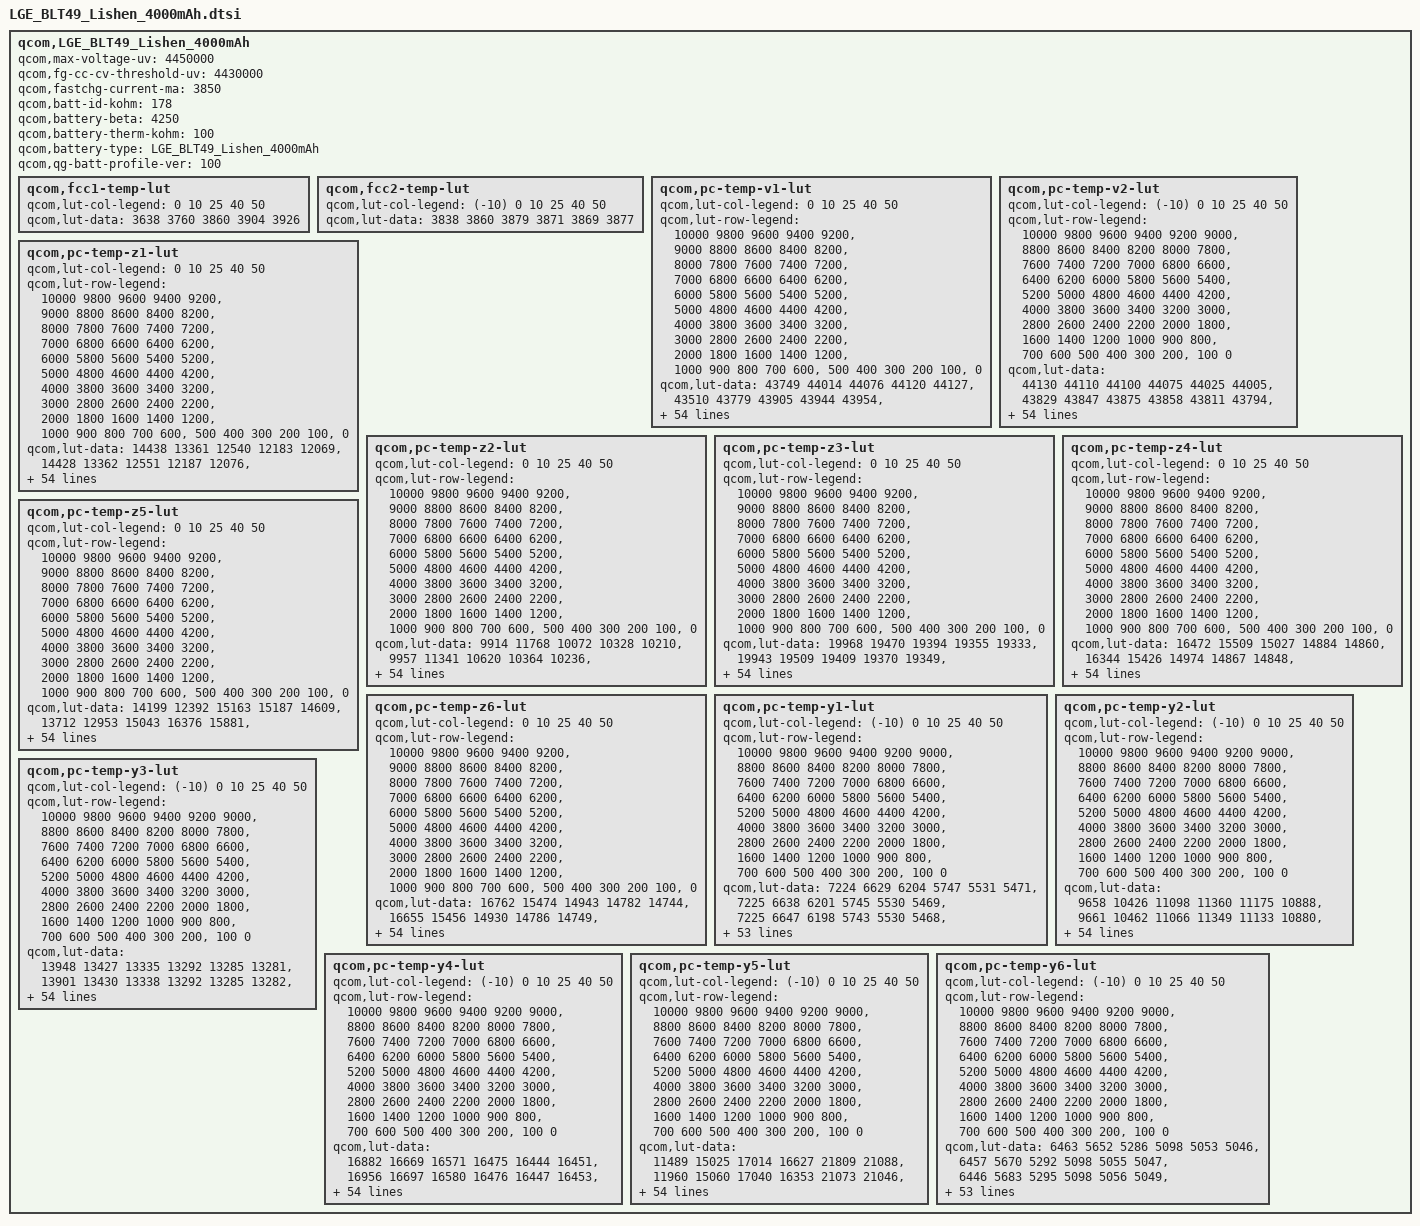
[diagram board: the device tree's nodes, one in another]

qcom,LGE_BLT49_Lishen_4000mAh {
    /* 4570460_LGE_BLT49lish_4000mAh_averaged_MasterSlave_May18th2020 */
    qcom,max-voltage-uv = <4450000>;
    qcom,fg-cc-cv-threshold-uv = <4430000>;
    qcom,fastchg-current-ma = <3850>;
    qcom,batt-id-kohm = <178>;
    qcom,battery-beta = <4250>;
    qcom,battery-therm-kohm = <100>;
    qcom,battery-type = "LGE_BLT49_Lishen_4000mAh";
    qcom,qg-batt-profile-ver = <100>;

	qcom,fcc1-temp-lut {
		qcom,lut-col-legend = <0 10 25 40 50>;
		qcom,lut-data = <3638 3760 3860 3904 3926>;
	};

	qcom,fcc2-temp-lut {
		qcom,lut-col-legend = <(-10) 0 10 25 40 50>;
		qcom,lut-data = <3838 3860 3879 3871 3869 3877>;
	};

	qcom,pc-temp-v1-lut {
		qcom,lut-col-legend = <0 10 25 40 50>;
		qcom,lut-row-legend = <10000 9800 9600 9400 9200>,
			<9000 8800 8600 8400 8200>,
			<8000 7800 7600 7400 7200>,
			<7000 6800 6600 6400 6200>,
			<6000 5800 5600 5400 5200>,
			<5000 4800 4600 4400 4200>,
			<4000 3800 3600 3400 3200>,
			<3000 2800 2600 2400 2200>,
			<2000 1800 1600 1400 1200>,
			<1000 900 800 700 600>,
			<500 400 300 200 100>,
			<0>;
		qcom,lut-data = <43749 44014 44076 44120 44127>,
			<43510 43779 43905 43944 43954>,
			<43273 43545 43719 43758 43769>,
			<43036 43312 43521 43561 43573>,
			<42802 43079 43309 43355 43368>,
			<42569 42846 43081 43136 43151>,
			<42337 42615 42847 42908 42922>,
			<42106 42384 42609 42678 42691>,
			<41876 42152 42368 42444 42455>,
			<41652 41916 42130 42208 42218>,
			<41432 41686 41896 41971 41983>,
			<41216 41462 41666 41735 41749>,
			<41005 41244 41442 41506 41520>,
			<40799 41034 41222 41284 41297>,
			<40598 40830 41008 41067 41078>,
			<40403 40632 40801 40856 40865>,
			<40213 40436 40600 40651 40657>,
			<40034 40242 40409 40454 40457>,
			<39866 40056 40227 40271 40271>,
			<39708 39883 40032 40082 40086>,
			<39559 39719 39794 39850 39870>,
			<39417 39546 39542 39582 39616>,
			<39285 39355 39332 39359 39389>,
			<39160 39163 39148 39194 39216>,
			<39042 38985 38993 39054 39068>,
			<38931 38816 38870 38922 38931>,
			<38829 38678 38765 38800 38803>,
			<38733 38581 38664 38689 38686>,
			<38646 38503 38567 38587 38580>,
			<38567 38432 38476 38492 38482>,
			<38495 38365 38392 38404 38393>,
			<38433 38306 38314 38321 38311>,
			<38381 38255 38244 38244 38236>,
			<38333 38211 38183 38176 38166>,
			<38287 38170 38128 38112 38099>,
			<38243 38133 38074 38047 38028>,
			<38197 38096 38026 37982 37950>,
			<38140 38048 37970 37910 37866>,
			<38074 37976 37892 37824 37773>,
			<37995 37887 37796 37724 37669>,
			<37892 37784 37694 37618 37559>,
			<37767 37662 37583 37506 37443>,
			<37621 37522 37453 37378 37312>,
			<37461 37366 37291 37220 37146>,
			<37311 37228 37157 37091 37028>,
			<37204 37140 37070 37009 36953>,
			<37166 37112 37043 36985 36930>,
			<37131 37081 37027 36966 36909>,
			<37094 37051 37005 36948 36887>,
			<37015 36986 36947 36885 36815>,
			<36787 36762 36704 36617 36526>,
			<36344 36314 36264 36182 36088>,
			<35767 35740 35699 35620 35523>,
			<34988 34962 34933 34863 34758>,
			<33714 33717 33726 33678 33555>,
			<30000 30000 30000 30000 30000>;
	};

	qcom,pc-temp-v2-lut {
		qcom,lut-col-legend = <(-10) 0 10 25 40 50>;
		qcom,lut-row-legend = <10000 9800 9600 9400 9200 9000>,
			<8800 8600 8400 8200 8000 7800>,
			<7600 7400 7200 7000 6800 6600>,
			<6400 6200 6000 5800 5600 5400>,
			<5200 5000 4800 4600 4400 4200>,
			<4000 3800 3600 3400 3200 3000>,
			<2800 2600 2400 2200 2000 1800>,
			<1600 1400 1200 1000 900 800>,
			<700 600 500 400 300 200>,
			<100 0>;
		qcom,lut-data = <44130 44110 44100 44075 44025 44005>,
			<43829 43847 43875 43858 43811 43794>,
			<43541 43594 43649 43640 43595 43581>,
			<43266 43353 43427 43421 43378 43367>,
			<43008 43126 43207 43202 43161 43152>,
			<42756 42900 42983 42979 42940 42933>,
			<42503 42662 42749 42746 42710 42703>,
			<42253 42419 42509 42508 42474 42468>,
			<42005 42178 42269 42271 42239 42233>,
			<41760 41940 42029 42035 42003 41997>,
			<41518 41706 41793 41801 41769 41763>,
			<41276 41472 41562 41570 41539 41533>,
			<41036 41242 41337 41342 41313 41307>,
			<40796 41011 41111 41119 41092 41087>,
			<40553 40781 40886 40904 40877 40872>,
			<40311 40550 40659 40694 40669 40664>,
			<40072 40316 40422 40490 40468 40464>,
			<39834 40075 40172 40295 40277 40272>,
			<39608 39842 39932 40091 40080 40076>,
			<39402 39623 39706 39856 39862 39865>,
			<39210 39416 39493 39608 39633 39648>,
			<39028 39223 39300 39383 39415 39433>,
			<38855 39044 39125 39175 39197 39209>,
			<38692 38877 38964 38991 39002 39009>,
			<38542 38725 38818 38840 38849 38854>,
			<38399 38585 38685 38712 38721 38725>,
			<38279 38448 38561 38593 38603 38606>,
			<38185 38301 38445 38483 38493 38494>,
			<38107 38165 38337 38381 38392 38391>,
			<38036 38067 38237 38286 38298 38296>,
			<37975 37995 38146 38198 38212 38209>,
			<37916 37932 38056 38116 38130 38126>,
			<37854 37878 37961 38041 38052 38049>,
			<37790 37829 37870 37969 37976 37972>,
			<37727 37778 37801 37893 37892 37880>,
			<37663 37725 37748 37813 37798 37771>,
			<37598 37668 37695 37731 37701 37659>,
			<37531 37604 37638 37645 37602 37554>,
			<37462 37533 37576 37556 37501 37453>,
			<37391 37452 37503 37466 37404 37355>,
			<37316 37357 37414 37377 37314 37264>,
			<37237 37253 37312 37281 37222 37169>,
			<37153 37150 37194 37164 37106 37049>,
			<37064 37045 37063 37034 36976 36921>,
			<36964 36943 36951 36934 36886 36835>,
			<36843 36845 36864 36868 36829 36781>,
			<36770 36795 36835 36853 36816 36768>,
			<36686 36741 36805 36838 36802 36753>,
			<36577 36676 36764 36809 36773 36719>,
			<36411 36575 36676 36734 36676 36598>,
			<36174 36369 36424 36469 36366 36256>,
			<35815 35973 35920 35992 35881 35762>,
			<35292 35381 35267 35364 35252 35119>,
			<34486 34507 34357 34497 34372 34228>,
			<33122 33078 32993 33192 33113 32956>,
			<28180 27841 27854 28000 28702 28124>;
	};

	qcom,pc-temp-z1-lut {
		qcom,lut-col-legend = <0 10 25 40 50>;
		qcom,lut-row-legend = <10000 9800 9600 9400 9200>,
			<9000 8800 8600 8400 8200>,
			<8000 7800 7600 7400 7200>,
			<7000 6800 6600 6400 6200>,
			<6000 5800 5600 5400 5200>,
			<5000 4800 4600 4400 4200>,
			<4000 3800 3600 3400 3200>,
			<3000 2800 2600 2400 2200>,
			<2000 1800 1600 1400 1200>,
			<1000 900 800 700 600>,
			<500 400 300 200 100>,
			<0>;
		qcom,lut-data = <14438 13361 12540 12183 12069>,
			<14428 13362 12551 12187 12076>,
			<14417 13364 12561 12190 12083>,
			<14404 13366 12564 12192 12089>,
			<14391 13366 12558 12192 12091>,
			<14377 13363 12554 12192 12091>,
			<14364 13360 12549 12191 12090>,
			<14350 13356 12544 12191 12091>,
			<14335 13352 12540 12190 12094>,
			<14321 13348 12537 12190 12097>,
			<14307 13344 12534 12191 12100>,
			<14294 13333 12533 12192 12102>,
			<14284 13318 12533 12193 12103>,
			<14274 13312 12534 12193 12104>,
			<14263 13318 12535 12194 12105>,
			<14246 13326 12535 12195 12106>,
			<14217 13330 12535 12195 12108>,
			<14190 13334 12536 12196 12110>,
			<14172 13337 12540 12199 12111>,
			<14158 13341 12544 12202 12113>,
			<14150 13344 12547 12204 12115>,
			<14146 13345 12551 12206 12116>,
			<14143 13350 12555 12209 12118>,
			<14138 13357 12559 12212 12122>,
			<14121 13359 12563 12215 12126>,
			<14107 13362 12567 12219 12129>,
			<14111 13366 12572 12223 12131>,
			<14126 13371 12577 12227 12134>,
			<14138 13378 12581 12231 12138>,
			<14138 13385 12586 12235 12143>,
			<14134 13394 12590 12238 12147>,
			<14134 13403 12596 12241 12150>,
			<14141 13409 12601 12244 12153>,
			<14152 13414 12606 12248 12157>,
			<14161 13421 12612 12253 12160>,
			<14170 13435 12620 12258 12163>,
			<14181 13453 12628 12263 12166>,
			<14199 13465 12636 12268 12169>,
			<14227 13477 12645 12272 12173>,
			<14250 13486 12653 12277 12178>,
			<14266 13490 12660 12281 12182>,
			<14277 13495 12665 12287 12185>,
			<14281 13507 12672 12291 12189>,
			<14287 13527 12682 12294 12192>,
			<14268 13522 12691 12300 12196>,
			<14242 13528 12691 12302 12198>,
			<14262 13523 12694 12303 12199>,
			<14261 13517 12698 12306 12199>,
			<14258 13512 12700 12308 12201>,
			<14255 13531 12712 12313 12207>,
			<14278 13561 12726 12323 12213>,
			<14302 13584 12737 12333 12222>,
			<14294 13592 12766 12348 12236>,
			<14347 13615 12789 12371 12258>,
			<14347 13615 12789 12371 12258>,
			<14347 13615 12789 12371 12258>;
	};

	qcom,pc-temp-z2-lut {
		qcom,lut-col-legend = <0 10 25 40 50>;
		qcom,lut-row-legend = <10000 9800 9600 9400 9200>,
			<9000 8800 8600 8400 8200>,
			<8000 7800 7600 7400 7200>,
			<7000 6800 6600 6400 6200>,
			<6000 5800 5600 5400 5200>,
			<5000 4800 4600 4400 4200>,
			<4000 3800 3600 3400 3200>,
			<3000 2800 2600 2400 2200>,
			<2000 1800 1600 1400 1200>,
			<1000 900 800 700 600>,
			<500 400 300 200 100>,
			<0>;
		qcom,lut-data = <9914 11768 10072 10328 10210>,
			<9957 11341 10620 10364 10236>,
			<9993 10918 11041 10388 10256>,
			<10022 10549 11269 10402 10269>,
			<10042 10290 11251 10405 10275>,
			<10055 10199 11080 10393 10272>,
			<10060 10310 10916 10372 10266>,
			<10054 10451 10781 10423 10260>,
			<10040 10445 10639 10657 10242>,
			<10030 10284 10558 10786 10218>,
			<10023 10161 10544 10606 10196>,
			<10019 10157 10580 10349 10170>,
			<10016 10166 10677 10354 10160>,
			<10015 10186 10822 10653 10159>,
			<10014 10325 10895 10901 10160>,
			<10013 10485 10928 10950 10167>,
			<10012 10486 10958 10974 10182>,
			<10011 10367 10998 11002 10194>,
			<10011 10280 11046 11041 10197>,
			<10011 10286 11066 11066 10200>,
			<10011 10309 10881 10926 10208>,
			<10019 10329 10593 10575 10236>,
			<10033 10348 10491 10404 10261>,
			<10047 10364 10454 10353 10271>,
			<10066 10372 10439 10319 10279>,
			<10083 10378 10451 10332 10281>,
			<10091 10382 10479 10401 10299>,
			<10096 10385 10494 10442 10314>,
			<10102 10388 10499 10399 10286>,
			<10114 10392 10500 10333 10224>,
			<10128 10399 10500 10314 10181>,
			<10124 10407 10500 10310 10149>,
			<9933 10416 10503 10311 10131>,
			<9689 10426 10514 10320 10141>,
			<9614 10436 10529 10338 10173>,
			<9591 10446 10541 10358 10208>,
			<9580 10456 10551 10385 10251>,
			<9575 10467 10562 10416 10295>,
			<9571 10480 10580 10459 10332>,
			<9570 10495 10601 10510 10365>,
			<9582 10509 10613 10527 10376>,
			<9604 10523 10620 10518 10374>,
			<9620 10542 10627 10502 10369>,
			<9621 10575 10633 10477 10360>,
			<9473 10843 10720 10474 10362>,
			<9478 10961 10744 10505 10347>,
			<9542 11008 10754 10501 10377>,
			<9575 11012 10788 10536 10364>,
			<9585 11045 10862 10947 10419>,
			<9582 11053 10853 10960 10497>,
			<9558 10971 10857 10530 10344>,
			<9480 10847 10812 10381 10183>,
			<9380 10591 10828 10357 10126>,
			<9294 10421 10715 10888 10053>,
			<9294 10421 10715 10888 10053>,
			<9294 10421 10715 10888 10053>;
	};

	qcom,pc-temp-z3-lut {
		qcom,lut-col-legend = <0 10 25 40 50>;
		qcom,lut-row-legend = <10000 9800 9600 9400 9200>,
			<9000 8800 8600 8400 8200>,
			<8000 7800 7600 7400 7200>,
			<7000 6800 6600 6400 6200>,
			<6000 5800 5600 5400 5200>,
			<5000 4800 4600 4400 4200>,
			<4000 3800 3600 3400 3200>,
			<3000 2800 2600 2400 2200>,
			<2000 1800 1600 1400 1200>,
			<1000 900 800 700 600>,
			<500 400 300 200 100>,
			<0>;
		qcom,lut-data = <19968 19470 19394 19355 19333>,
			<19943 19509 19409 19370 19349>,
			<19908 19550 19424 19385 19364>,
			<19869 19589 19439 19397 19377>,
			<19832 19623 19454 19405 19387>,
			<19803 19648 19471 19408 19395>,
			<19790 19670 19482 19410 19401>,
			<19788 19686 19484 19415 19404>,
			<19791 19682 19482 19423 19405>,
			<19793 19650 19479 19427 19406>,
			<19796 19619 19473 19418 19404>,
			<19798 19606 19471 19405 19398>,
			<19798 19597 19476 19403 19393>,
			<19796 19595 19484 19408 19388>,
			<19793 19611 19484 19412 19383>,
			<19788 19629 19481 19410 19380>,
			<19777 19625 19476 19406 19378>,
			<19764 19590 19472 19403 19376>,
			<19750 19563 19468 19399 19372>,
			<19735 19559 19465 19395 19368>,
			<19719 19557 19464 19393 19367>,
			<19702 19557 19464 19392 19367>,
			<19683 19573 19462 19389 19367>,
			<19665 19593 19453 19379 19369>,
			<19646 19598 19443 19370 19373>,
			<19628 19599 19435 19375 19380>,
			<19611 19598 19429 19398 19400>,
			<19596 19594 19428 19413 19414>,
			<19580 19588 19429 19411 19411>,
			<19564 19582 19431 19407 19405>,
			<19545 19579 19433 19404 19399>,
			<19522 19575 19438 19400 19391>,
			<19484 19571 19441 19396 19384>,
			<19444 19568 19440 19391 19375>,
			<19421 19564 19439 19386 19366>,
			<19404 19561 19438 19381 19362>,
			<19395 19558 19436 19377 19360>,
			<19393 19554 19433 19374 19359>,
			<19391 19551 19432 19374 19358>,
			<19391 19547 19430 19375 19357>,
			<19391 19542 19427 19375 19356>,
			<19390 19534 19422 19372 19357>,
			<19384 19525 19418 19370 19360>,
			<19360 19511 19416 19369 19366>,
			<19277 19447 19403 19365 19360>,
			<19276 19366 19394 19358 19351>,
			<19271 19308 19394 19350 19342>,
			<19269 19300 19371 19345 19339>,
			<19269 19293 19356 19304 19333>,
			<19269 19291 19369 19304 19326>,
			<19269 19296 19361 19348 19349>,
			<19272 19301 19362 19360 19359>,
			<19278 19306 19349 19359 19363>,
			<19290 19312 19345 19309 19364>,
			<19290 19312 19345 19309 19364>,
			<19290 19312 19345 19309 19364>;
	};

	qcom,pc-temp-z4-lut {
		qcom,lut-col-legend = <0 10 25 40 50>;
		qcom,lut-row-legend = <10000 9800 9600 9400 9200>,
			<9000 8800 8600 8400 8200>,
			<8000 7800 7600 7400 7200>,
			<7000 6800 6600 6400 6200>,
			<6000 5800 5600 5400 5200>,
			<5000 4800 4600 4400 4200>,
			<4000 3800 3600 3400 3200>,
			<3000 2800 2600 2400 2200>,
			<2000 1800 1600 1400 1200>,
			<1000 900 800 700 600>,
			<500 400 300 200 100>,
			<0>;
		qcom,lut-data = <16472 15509 15027 14884 14860>,
			<16344 15426 14974 14867 14848>,
			<16220 15342 14925 14849 14835>,
			<16099 15259 14880 14831 14821>,
			<15981 15176 14839 14813 14806>,
			<15866 15091 14800 14795 14790>,
			<15755 14987 14770 14775 14773>,
			<15644 14901 14750 14751 14756>,
			<15537 14883 14735 14719 14738>,
			<15446 14882 14730 14700 14723>,
			<15367 14880 14713 14700 14714>,
			<15299 14870 14695 14702 14708>,
			<15240 14848 14678 14697 14703>,
			<15189 14817 14655 14677 14698>,
			<15147 14760 14645 14662 14695>,
			<15115 14707 14640 14658 14691>,
			<15089 14706 14638 14654 14687>,
			<15069 14739 14636 14653 14685>,
			<15056 14763 14636 14653 14683>,
			<15045 14759 14636 14653 14683>,
			<15038 14751 14671 14677 14695>,
			<15034 14747 14734 14750 14752>,
			<15030 14751 14770 14792 14790>,
			<15029 14758 14796 14801 14787>,
			<15030 14770 14809 14806 14779>,
			<15033 14798 14803 14797 14766>,
			<15039 14815 14787 14757 14733>,
			<15051 14811 14771 14725 14707>,
			<15065 14801 14756 14712 14700>,
			<15078 14791 14741 14703 14695>,
			<15091 14783 14727 14695 14691>,
			<15111 14775 14714 14688 14686>,
			<15150 14767 14705 14683 14682>,
			<15187 14760 14699 14679 14679>,
			<15195 14753 14695 14676 14675>,
			<15194 14744 14693 14676 14675>,
			<15192 14736 14692 14678 14677>,
			<15180 14730 14692 14682 14681>,
			<15147 14727 14695 14688 14688>,
			<15113 14724 14701 14696 14699>,
			<15086 14720 14702 14699 14703>,
			<15061 14715 14693 14692 14694>,
			<15042 14710 14686 14689 14688>,
			<15022 14702 14684 14691 14692>,
			<14992 14697 14665 14676 14677>,
			<14986 14773 14656 14665 14666>,
			<14981 14830 14650 14663 14663>,
			<14975 14832 14660 14653 14650>,
			<14969 14833 14669 14682 14637>,
			<14964 14833 14650 14677 14638>,
			<14971 14834 14674 14662 14659>,
			<15000 14851 14683 14661 14661>,
			<15025 14858 14703 14667 14662>,
			<15048 14867 14713 14725 14664>,
			<15048 14867 14713 14725 14664>,
			<15048 14867 14713 14725 14664>;
	};

	qcom,pc-temp-z5-lut {
		qcom,lut-col-legend = <0 10 25 40 50>;
		qcom,lut-row-legend = <10000 9800 9600 9400 9200>,
			<9000 8800 8600 8400 8200>,
			<8000 7800 7600 7400 7200>,
			<7000 6800 6600 6400 6200>,
			<6000 5800 5600 5400 5200>,
			<5000 4800 4600 4400 4200>,
			<4000 3800 3600 3400 3200>,
			<3000 2800 2600 2400 2200>,
			<2000 1800 1600 1400 1200>,
			<1000 900 800 700 600>,
			<500 400 300 200 100>,
			<0>;
		qcom,lut-data = <14199 12392 15163 15187 14609>,
			<13712 12953 15043 16376 15881>,
			<13460 13618 15180 17495 17109>,
			<13397 14354 15484 18449 18287>,
			<13480 15124 16064 19136 19412>,
			<13663 15915 17345 19528 20472>,
			<13905 16987 18618 19873 21490>,
			<14269 17897 19830 20865 22519>,
			<14757 17987 20873 23178 23632>,
			<15234 17567 21234 24521 24614>,
			<15695 17222 22894 23938 25328>,
			<16163 17312 25167 23100 25920>,
			<16646 17682 28340 23989 26118>,
			<17200 18471 32903 28587 25977>,
			<17653 22874 35618 32401 25814>,
			<17890 27868 37387 33686 26204>,
			<18060 27917 38681 34980 27711>,
			<18133 24164 39244 35473 28684>,
			<18063 21384 39510 35493 28852>,
			<17886 21625 39960 35439 28865>,
			<17670 22640 42436 34180 28212>,
			<17350 24486 45637 30549 25344>,
			<16950 33307 44892 26894 22348>,
			<16558 43640 35775 21956 19930>,
			<16146 46375 27033 17611 17956>,
			<15739 46208 23676 17629 18185>,
			<15371 45007 21411 20172 22217>,
			<15012 41937 20875 22317 26013>,
			<14673 37556 21080 23174 27435>,
			<14369 35203 21478 23849 28374>,
			<14067 34132 22539 24880 28560>,
			<13691 33494 25046 26489 28321>,
			<13100 33308 27544 27764 27950>,
			<12515 33207 29826 28397 27448>,
			<12218 33163 31830 28840 26759>,
			<12032 33327 32990 28941 26528>,
			<11926 33768 33834 28907 27215>,
			<11900 34398 34347 28842 27901>,
			<11884 35851 34474 28696 27243>,
			<11878 37167 34311 28350 25336>,
			<11966 36730 33617 27786 24274>,
			<12086 34490 30914 26197 24272>,
			<12089 32625 29827 25183 24863>,
			<12059 30811 29977 24948 28071>,
			<11698 24642 30727 25637 27293>,
			<11662 17115 29059 24019 22997>,
			<11593 12526 29878 21432 20188>,
			<11557 12341 21172 22286 21129>,
			<11556 12187 18200 18322 22773>,
			<11570 12182 22048 18762 20882>,
			<11626 12297 18723 20079 22006>,
			<11619 12184 17330 20058 20729>,
			<11469 12122 15181 18816 19424>,
			<11407 12069 14528 13993 17863>,
			<11407 12069 14528 13993 17863>,
			<11407 12069 14528 13993 17863>;
	};

	qcom,pc-temp-z6-lut {
		qcom,lut-col-legend = <0 10 25 40 50>;
		qcom,lut-row-legend = <10000 9800 9600 9400 9200>,
			<9000 8800 8600 8400 8200>,
			<8000 7800 7600 7400 7200>,
			<7000 6800 6600 6400 6200>,
			<6000 5800 5600 5400 5200>,
			<5000 4800 4600 4400 4200>,
			<4000 3800 3600 3400 3200>,
			<3000 2800 2600 2400 2200>,
			<2000 1800 1600 1400 1200>,
			<1000 900 800 700 600>,
			<500 400 300 200 100>,
			<0>;
		qcom,lut-data = <16762 15474 14943 14782 14744>,
			<16655 15456 14930 14786 14749>,
			<16552 15433 14917 14787 14753>,
			<16454 15407 14906 14786 14755>,
			<16362 15379 14895 14783 14755>,
			<16279 15350 14886 14778 14753>,
			<16204 15316 14876 14770 14749>,
			<16137 15281 14868 14763 14744>,
			<16077 15253 14859 14756 14739>,
			<16026 15231 14851 14749 14733>,
			<15984 15211 14841 14743 14727>,
			<15947 15192 14832 14738 14722>,
			<15911 15175 14826 14733 14717>,
			<15876 15159 14821 14728 14712>,
			<15844 15143 14816 14725 14708>,
			<15815 15129 14813 14721 14705>,
			<15787 15123 14810 14718 14703>,
			<15763 15120 14807 14716 14700>,
			<15742 15118 14805 14713 14698>,
			<15724 15115 14804 14712 14696>,
			<15707 15113 14820 14722 14700>,
			<15690 15112 14848 14753 14725>,
			<15675 15122 14860 14768 14742>,
			<15661 15137 14866 14768 14743>,
			<15648 15150 14869 14767 14743>,
			<15640 15164 14865 14765 14742>,
			<15640 15172 14856 14761 14739>,
			<15642 15170 14849 14757 14736>,
			<15643 15165 14843 14751 14732>,
			<15643 15161 14839 14746 14727>,
			<15642 15157 14836 14741 14723>,
			<15642 15154 14833 14736 14717>,
			<15638 15151 14831 14732 14711>,
			<15633 15149 14829 14728 14705>,
			<15632 15148 14828 14724 14699>,
			<15632 15147 14828 14723 14697>,
			<15633 15147 14828 14722 14698>,
			<15635 15147 14828 14722 14699>,
			<15642 15147 14830 14724 14701>,
			<15646 15148 14833 14729 14705>,
			<15646 15148 14834 14731 14707>,
			<15644 15148 14829 14727 14705>,
			<15639 15147 14826 14726 14703>,
			<15625 15143 14825 14727 14709>,
			<15583 15117 14814 14719 14700>,
			<15583 15110 14807 14711 14691>,
			<15582 15107 14804 14706 14685>,
			<15584 15106 14799 14699 14677>,
			<15586 15106 14795 14692 14669>,
			<15591 15113 14796 14690 14666>,
			<15607 15127 14806 14708 14689>,
			<15631 15144 14815 14717 14698>,
			<15659 15165 14822 14722 14704>,
			<15692 15194 14834 14727 14710>,
			<15692 15194 14834 14727 14710>,
			<15692 15194 14834 14727 14710>;
	};

	qcom,pc-temp-y1-lut {
		qcom,lut-col-legend = <(-10) 0 10 25 40 50>;
		qcom,lut-row-legend = <10000 9800 9600 9400 9200 9000>,
			<8800 8600 8400 8200 8000 7800>,
			<7600 7400 7200 7000 6800 6600>,
			<6400 6200 6000 5800 5600 5400>,
			<5200 5000 4800 4600 4400 4200>,
			<4000 3800 3600 3400 3200 3000>,
			<2800 2600 2400 2200 2000 1800>,
			<1600 1400 1200 1000 900 800>,
			<700 600 500 400 300 200>,
			<100 0>;
		qcom,lut-data = <7224 6629 6204 5747 5531 5471>,
			<7225 6638 6201 5745 5530 5469>,
			<7225 6647 6198 5743 5530 5468>,
			<7225 6654 6197 5741 5529 5467>,
			<7226 6660 6196 5739 5529 5466>,
			<7226 6662 6196 5738 5529 5466>,
			<7226 6661 6196 5737 5529 5466>,
			<7226 6658 6196 5736 5529 5467>,
			<7227 6656 6194 5735 5529 5467>,
			<7231 6656 6189 5735 5529 5467>,
			<7236 6656 6185 5735 5528 5468>,
			<7243 6657 6186 5735 5528 5468>,
			<7262 6660 6189 5734 5528 5469>,
			<7273 6664 6192 5734 5528 5470>,
			<7264 6671 6191 5735 5528 5470>,
			<7251 6678 6191 5736 5529 5470>,
			<7252 6682 6193 5737 5530 5471>,
			<7276 6687 6199 5737 5531 5473>,
			<7297 6691 6204 5737 5532 5474>,
			<7286 6689 6208 5738 5532 5475>,
			<7262 6685 6212 5740 5533 5476>,
			<7253 6684 6212 5741 5534 5477>,
			<7245 6692 6208 5743 5535 5478>,
			<7234 6702 6205 5744 5536 5479>,
			<7232 6704 6211 5746 5538 5481>,
			<7234 6702 6226 5749 5540 5483>,
			<7236 6699 6231 5751 5542 5484>,
			<7237 6697 6227 5753 5544 5486>,
			<7239 6694 6223 5755 5546 5487>,
			<7239 6695 6225 5758 5548 5488>,
			<7238 6701 6231 5761 5550 5490>,
			<7237 6705 6234 5764 5553 5492>,
			<7238 6701 6232 5767 5555 5494>,
			<7242 6696 6228 5769 5557 5496>,
			<7245 6695 6227 5771 5559 5498>,
			<7245 6696 6227 5774 5561 5499>,
			<7245 6699 6228 5777 5563 5500>,
			<7246 6709 6229 5780 5564 5502>,
			<7249 6728 6231 5783 5565 5504>,
			<7253 6734 6233 5786 5566 5505>,
			<7255 6722 6239 5788 5569 5507>,
			<7257 6710 6247 5791 5571 5508>,
			<7259 6710 6256 5794 5574 5510>,
			<7265 6714 6264 5798 5577 5512>,
			<7274 6719 6262 5804 5580 5515>,
			<7301 6727 6260 5810 5583 5518>,
			<7317 6731 6273 5813 5583 5517>,
			<7335 6737 6280 5816 5583 5518>,
			<7329 6752 6274 5815 5585 5520>,
			<7331 6764 6296 5817 5585 5520>,
			<7397 6781 6298 5822 5588 5524>,
			<7501 6812 6302 5829 5595 5531>,
			<7577 6863 6329 5848 5609 5542>,
			<7708 6990 6388 5874 5625 5559>,
			<7708 6990 6388 5874 5625 5559>,
			<7708 6990 6388 5874 5625 5559>;
	};

	qcom,pc-temp-y2-lut {
		qcom,lut-col-legend = <(-10) 0 10 25 40 50>;
		qcom,lut-row-legend = <10000 9800 9600 9400 9200 9000>,
			<8800 8600 8400 8200 8000 7800>,
			<7600 7400 7200 7000 6800 6600>,
			<6400 6200 6000 5800 5600 5400>,
			<5200 5000 4800 4600 4400 4200>,
			<4000 3800 3600 3400 3200 3000>,
			<2800 2600 2400 2200 2000 1800>,
			<1600 1400 1200 1000 900 800>,
			<700 600 500 400 300 200>,
			<100 0>;
		qcom,lut-data = <9658 10426 11098 11360 11175 10888>,
			<9661 10462 11066 11349 11133 10880>,
			<9663 10499 11036 11327 11071 10869>,
			<9666 10534 11006 11297 11003 10856>,
			<9668 10564 10979 11263 10944 10842>,
			<9670 10587 10953 11229 10909 10826>,
			<9672 10602 10928 11192 10896 10808>,
			<9674 10613 10905 11149 10887 10789>,
			<9675 10625 10893 11117 10882 10772>,
			<9677 10640 10887 11084 10882 10752>,
			<9679 10658 10884 11058 10882 10736>,
			<9680 10687 10892 11050 10881 10739>,
			<9682 10734 10922 11045 10881 10754>,
			<9682 10780 10956 11044 10881 10763>,
			<9682 10822 10992 11054 10890 10763>,
			<9680 10862 11029 11075 10910 10766>,
			<9679 10893 11057 11103 10939 10787>,
			<9678 10918 11078 11150 10997 10849>,
			<9676 10940 11099 11184 11054 10919>,
			<9675 10959 11123 11196 11101 10993>,
			<9673 10977 11147 11204 11145 11062>,
			<9672 10997 11168 11220 11153 11074>,
			<9671 11026 11186 11265 11111 11035>,
			<9671 11048 11202 11308 11071 11001>,
			<9670 11046 11220 11324 11090 11007>,
			<9669 11031 11239 11334 11150 11031>,
			<9669 11015 11252 11345 11186 11055>,
			<9668 11003 11261 11358 11195 11074>,
			<9667 10985 11268 11371 11202 11096>,
			<9666 10850 11274 11381 11218 11140>,
			<9666 10287 11280 11390 11254 11213>,
			<9665 9853 11283 11396 11274 11248>,
			<9664 9785 11277 11403 11290 11221>,
			<9664 9749 11271 11407 11315 11185>,
			<9663 9722 11271 11401 11320 11176>,
			<9662 9699 11271 11388 11300 11166>,
			<9662 9684 11266 11376 11276 11153>,
			<9661 9678 11245 11369 11258 11125>,
			<9661 9674 11209 11362 11241 11089>,
			<9661 9671 11172 11361 11234 11075>,
			<9661 9667 11132 11362 11233 11072>,
			<9660 9665 11085 11363 11232 11069>,
			<9660 9663 11022 11358 11218 11047>,
			<9660 9661 10935 11343 11172 11000>,
			<9660 9660 10821 11306 11080 10917>,
			<9659 9659 10700 11226 10979 10817>,
			<9658 9658 10647 11203 10990 10822>,
			<9658 9658 10646 11191 11011 10853>,
			<9657 9658 10694 11211 11025 10864>,
			<9657 9657 10662 11237 11025 10843>,
			<9656 9656 10482 11217 11012 10799>,
			<9653 9655 9841 11185 10908 10736>,
			<9650 9653 9693 11089 10809 10641>,
			<9649 9650 9664 10941 10664 10476>,
			<9649 9650 9664 10941 10664 10476>,
			<9649 9650 9664 10941 10664 10476>;
	};

	qcom,pc-temp-y3-lut {
		qcom,lut-col-legend = <(-10) 0 10 25 40 50>;
		qcom,lut-row-legend = <10000 9800 9600 9400 9200 9000>,
			<8800 8600 8400 8200 8000 7800>,
			<7600 7400 7200 7000 6800 6600>,
			<6400 6200 6000 5800 5600 5400>,
			<5200 5000 4800 4600 4400 4200>,
			<4000 3800 3600 3400 3200 3000>,
			<2800 2600 2400 2200 2000 1800>,
			<1600 1400 1200 1000 900 800>,
			<700 600 500 400 300 200>,
			<100 0>;
		qcom,lut-data = <13948 13427 13335 13292 13285 13281>,
			<13901 13430 13338 13292 13285 13282>,
			<13856 13436 13342 13293 13286 13283>,
			<13814 13443 13346 13293 13286 13284>,
			<13776 13448 13349 13294 13287 13285>,
			<13742 13451 13351 13294 13288 13285>,
			<13713 13451 13353 13295 13288 13286>,
			<13687 13450 13354 13296 13289 13287>,
			<13664 13450 13354 13297 13290 13287>,
			<13644 13448 13354 13301 13290 13287>,
			<13625 13445 13353 13305 13291 13288>,
			<13604 13442 13354 13305 13291 13288>,
			<13582 13440 13356 13304 13291 13288>,
			<13565 13437 13357 13304 13292 13289>,
			<13556 13430 13357 13305 13293 13291>,
			<13549 13421 13357 13308 13295 13293>,
			<13539 13414 13356 13310 13297 13294>,
			<13525 13409 13351 13311 13298 13295>,
			<13513 13403 13346 13312 13299 13295>,
			<13506 13397 13341 13311 13298 13294>,
			<13501 13390 13337 13308 13295 13291>,
			<13498 13384 13334 13304 13292 13289>,
			<13495 13379 13331 13297 13288 13285>,
			<13492 13376 13329 13292 13285 13283>,
			<13489 13372 13328 13292 13284 13282>,
			<13484 13369 13328 13293 13284 13283>,
			<13481 13365 13328 13295 13284 13282>,
			<13487 13357 13327 13295 13284 13281>,
			<13500 13348 13327 13296 13283 13280>,
			<13517 13343 13327 13296 13283 13280>,
			<13542 13339 13327 13297 13284 13281>,
			<13572 13337 13327 13298 13284 13281>,
			<13602 13343 13324 13298 13285 13282>,
			<13634 13355 13319 13298 13286 13283>,
			<13669 13366 13319 13298 13286 13283>,
			<13710 13375 13321 13298 13286 13282>,
			<13754 13386 13324 13297 13285 13281>,
			<13797 13404 13326 13297 13285 13282>,
			<13843 13430 13328 13296 13284 13282>,
			<13888 13462 13329 13296 13284 13283>,
			<13930 13505 13330 13295 13285 13283>,
			<13970 13558 13331 13295 13286 13284>,
			<14014 13621 13332 13294 13285 13283>,
			<14059 13698 13333 13292 13283 13282>,
			<14113 13784 13336 13292 13284 13283>,
			<14180 13876 13345 13296 13288 13288>,
			<14227 13919 13354 13302 13293 13292>,
			<14295 13946 13357 13306 13297 13295>,
			<14306 13898 13354 13306 13297 13294>,
			<14295 13940 13361 13306 13294 13291>,
			<14500 14040 13363 13300 13290 13288>,
			<15031 14216 13370 13298 13289 13289>,
			<16425 14642 13444 13301 13291 13292>,
			<20918 16414 13676 13307 13296 13298>,
			<20918 16414 13676 13307 13296 13298>,
			<20918 16414 13676 13307 13296 13298>;
	};

	qcom,pc-temp-y4-lut {
		qcom,lut-col-legend = <(-10) 0 10 25 40 50>;
		qcom,lut-row-legend = <10000 9800 9600 9400 9200 9000>,
			<8800 8600 8400 8200 8000 7800>,
			<7600 7400 7200 7000 6800 6600>,
			<6400 6200 6000 5800 5600 5400>,
			<5200 5000 4800 4600 4400 4200>,
			<4000 3800 3600 3400 3200 3000>,
			<2800 2600 2400 2200 2000 1800>,
			<1600 1400 1200 1000 900 800>,
			<700 600 500 400 300 200>,
			<100 0>;
		qcom,lut-data = <16882 16669 16571 16475 16444 16451>,
			<16956 16697 16580 16476 16447 16453>,
			<17052 16756 16595 16479 16450 16454>,
			<17150 16827 16612 16481 16453 16455>,
			<17229 16889 16626 16484 16455 16457>,
			<17268 16921 16634 16486 16458 16458>,
			<17264 16923 16635 16490 16459 16459>,
			<17248 16924 16636 16493 16461 16459>,
			<17231 16924 16637 16494 16463 16461>,
			<17214 16926 16644 16494 16465 16463>,
			<17197 16928 16653 16494 16469 16466>,
			<17183 16927 16662 16497 16473 16469>,
			<17171 16924 16673 16510 16479 16473>,
			<17156 16919 16680 16524 16485 16477>,
			<17121 16913 16682 16535 16491 16481>,
			<17072 16904 16684 16546 16498 16485>,
			<17030 16887 16680 16562 16510 16494>,
			<16991 16846 16659 16584 16532 16511>,
			<16957 16803 16634 16597 16545 16522>,
			<16928 16774 16610 16579 16541 16524>,
			<16903 16749 16586 16540 16531 16525>,
			<16876 16726 16572 16513 16517 16521>,
			<16843 16703 16563 16492 16486 16488>,
			<16812 16681 16556 16480 16461 16460>,
			<16795 16662 16551 16477 16459 16459>,
			<16783 16645 16548 16476 16461 16460>,
			<16777 16627 16546 16475 16463 16461>,
			<16781 16600 16545 16477 16468 16466>,
			<16787 16576 16544 16481 16475 16473>,
			<16788 16579 16542 16486 16482 16480>,
			<16784 16611 16541 16492 16490 16488>,
			<16780 16639 16539 16498 16497 16495>,
			<16783 16649 16530 16506 16504 16505>,
			<16792 16655 16519 16513 16510 16513>,
			<16799 16663 16517 16514 16510 16512>,
			<16803 16675 16520 16509 16503 16501>,
			<16806 16686 16525 16502 16493 16489>,
			<16812 16690 16532 16491 16484 16482>,
			<16820 16693 16540 16477 16473 16476>,
			<16831 16695 16547 16472 16470 16475>,
			<16846 16695 16553 16473 16474 16480>,
			<16866 16696 16557 16474 16478 16485>,
			<16888 16697 16556 16473 16472 16476>,
			<16912 16706 16552 16468 16456 16456>,
			<16941 16724 16556 16469 16456 16458>,
			<16978 16763 16578 16479 16471 16480>,
			<16984 16791 16608 16499 16503 16519>,
			<16982 16816 16620 16523 16535 16549>,
			<16943 16788 16620 16537 16549 16561>,
			<16855 16792 16651 16551 16547 16546>,
			<16861 16797 16643 16503 16478 16474>,
			<16961 16765 16637 16475 16463 16465>,
			<17387 16787 16671 16478 16464 16465>,
			<19693 17424 16780 16493 16472 16474>,
			<19693 17424 16780 16493 16472 16474>,
			<19693 17424 16780 16493 16472 16474>;
	};

	qcom,pc-temp-y5-lut {
		qcom,lut-col-legend = <(-10) 0 10 25 40 50>;
		qcom,lut-row-legend = <10000 9800 9600 9400 9200 9000>,
			<8800 8600 8400 8200 8000 7800>,
			<7600 7400 7200 7000 6800 6600>,
			<6400 6200 6000 5800 5600 5400>,
			<5200 5000 4800 4600 4400 4200>,
			<4000 3800 3600 3400 3200 3000>,
			<2800 2600 2400 2200 2000 1800>,
			<1600 1400 1200 1000 900 800>,
			<700 600 500 400 300 200>,
			<100 0>;
		qcom,lut-data = <11489 15025 17014 16627 21809 21088>,
			<11960 15060 17040 16353 21073 21046>,
			<12437 15149 17025 16013 20303 20875>,
			<12888 15277 16977 15653 19559 20610>,
			<13281 15431 16904 15318 18901 20285>,
			<13583 15596 16815 15053 18394 19935>,
			<13785 15783 16709 14829 18054 19558>,
			<13937 16002 16575 14612 17779 19109>,
			<14073 16200 16397 14587 17466 18569>,
			<14218 16363 16052 15259 17045 17796>,
			<14328 16538 15767 15968 16577 17037>,
			<14354 16781 15879 15757 16056 16497>,
			<14350 17103 16411 14851 15453 16020>,
			<14357 17464 17079 14375 15190 15840>,
			<14642 17854 18042 14556 15237 16092>,
			<15090 18303 19101 14955 15340 16421>,
			<15164 18891 19813 15537 15472 16414>,
			<14792 19756 20397 16688 15687 16132>,
			<14438 20363 20677 18135 16053 15947>,
			<14375 20501 20665 20296 17982 17332>,
			<14349 20576 20596 22683 21099 19760>,
			<14332 20744 20489 22987 21934 20402>,
			<14294 21228 20261 19751 20837 20189>,
			<14218 21833 20092 16770 19517 19886>,
			<13947 22440 20300 16971 18834 19524>,
			<13146 23133 20901 18160 18337 18945>,
			<12496 23371 21432 18933 17891 18223>,
			<12228 21227 21787 19337 17379 17000>,
			<12046 17771 22175 19708 17000 15973>,
			<12028 15537 22934 20029 17017 15912>,
			<12240 13729 24148 20704 17337 16129>,
			<12437 12831 24705 21409 17773 16450>,
			<12416 12988 23019 22135 18403 17110>,
			<12323 13269 20625 22908 19246 17970>,
			<12282 13362 20333 23508 20076 18553>,
			<12363 13462 21421 24350 21069 18943>,
			<12491 13601 22434 24937 21708 19369>,
			<12589 13745 22845 24942 21684 20145>,
			<12712 13922 23121 24864 21571 21012>,
			<12820 13981 23121 24705 21521 21226>,
			<12882 13782 22630 23991 21601 20897>,
			<12944 13535 21988 22872 21650 20570>,
			<13042 13540 21336 21374 21356 20878>,
			<13293 13664 20340 19277 20537 21583>,
			<13584 13682 19278 18324 19388 20341>,
			<13862 13731 18528 18494 17608 17195>,
			<14061 13760 18284 19031 16879 15773>,
			<14570 13805 18359 19281 16600 15354>,
			<14986 14169 19383 19809 16982 15662>,
			<15115 14760 19530 19577 16453 15276>,
			<14996 14648 18715 19129 17542 16651>,
			<13584 14263 14481 20092 17512 17001>,
			<11572 13662 14183 19801 17888 17285>,
			<9850 11142 13802 20803 20059 21679>,
			<9850 11142 13802 20803 20059 21679>,
			<9850 11142 13802 20803 20059 21679>;
	};

	qcom,pc-temp-y6-lut {
		qcom,lut-col-legend = <(-10) 0 10 25 40 50>;
		qcom,lut-row-legend = <10000 9800 9600 9400 9200 9000>,
			<8800 8600 8400 8200 8000 7800>,
			<7600 7400 7200 7000 6800 6600>,
			<6400 6200 6000 5800 5600 5400>,
			<5200 5000 4800 4600 4400 4200>,
			<4000 3800 3600 3400 3200 3000>,
			<2800 2600 2400 2200 2000 1800>,
			<1600 1400 1200 1000 900 800>,
			<700 600 500 400 300 200>,
			<100 0>;
		qcom,lut-data = <6463 5652 5286 5098 5053 5046>,
			<6457 5670 5292 5098 5055 5047>,
			<6446 5683 5295 5098 5056 5049>,
			<6430 5693 5297 5098 5057 5050>,
			<6411 5699 5298 5099 5058 5051>,
			<6389 5702 5298 5100 5060 5052>,
			<6362 5700 5297 5101 5061 5053>,
			<6331 5694 5295 5102 5062 5054>,
			<6302 5688 5293 5103 5063 5055>,
			<6277 5680 5292 5105 5064 5056>,
			<6253 5673 5292 5107 5065 5057>,
			<6232 5668 5293 5109 5067 5058>,
			<6212 5663 5295 5112 5069 5059>,
			<6193 5658 5296 5115 5071 5061>,
			<6173 5651 5295 5119 5074 5064>,
			<6153 5642 5295 5125 5077 5066>,
			<6135 5631 5293 5130 5082 5070>,
			<6117 5615 5282 5137 5089 5076>,
			<6102 5601 5271 5141 5093 5079>,
			<6090 5591 5261 5135 5091 5078>,
			<6080 5582 5251 5122 5086 5076>,
			<6073 5575 5245 5111 5080 5073>,
			<6066 5569 5241 5100 5068 5061>,
			<6062 5564 5238 5093 5059 5051>,
			<6061 5563 5237 5093 5058 5051>,
			<6061 5562 5237 5094 5058 5051>,
			<6062 5560 5237 5095 5059 5052>,
			<6070 5555 5238 5096 5060 5053>,
			<6087 5550 5239 5098 5062 5054>,
			<6105 5551 5240 5100 5064 5056>,
			<6124 5563 5243 5103 5067 5059>,
			<6147 5578 5244 5105 5070 5062>,
			<6174 5597 5242 5108 5073 5065>,
			<6206 5620 5238 5111 5075 5068>,
			<6239 5646 5239 5111 5075 5068>,
			<6272 5677 5245 5110 5073 5064>,
			<6306 5713 5254 5108 5070 5060>,
			<6342 5751 5262 5106 5067 5059>,
			<6382 5793 5272 5102 5064 5058>,
			<6421 5839 5283 5101 5063 5058>,
			<6457 5890 5296 5102 5065 5060>,
			<6492 5947 5311 5103 5067 5061>,
			<6532 6010 5327 5102 5065 5059>,
			<6578 6081 5346 5101 5060 5053>,
			<6634 6161 5375 5102 5060 5054>,
			<6706 6251 5418 5110 5069 5065>,
			<6754 6300 5450 5122 5082 5080>,
			<6819 6334 5457 5131 5094 5090>,
			<6831 6300 5441 5135 5097 5093>,
			<6817 6340 5466 5138 5095 5087>,
			<6998 6430 5490 5121 5072 5064>,
			<7505 6574 5525 5114 5068 5063>,
			<8798 6945 5655 5120 5072 5066>,
			<12817 8546 5968 5134 5080 5076>,
			<12817 8546 5968 5134 5080 5076>,
			<12817 8546 5968 5134 5080 5076>;
	};

};
